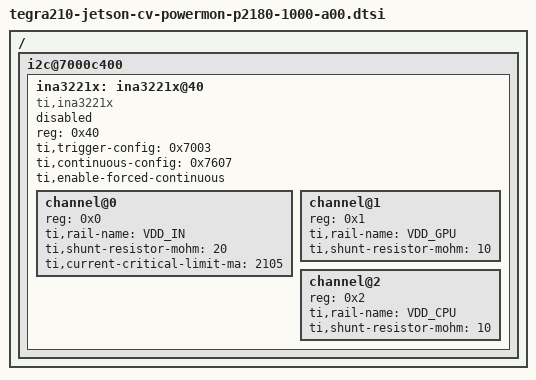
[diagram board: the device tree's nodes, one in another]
/*
 * Copyright (c) 2015, NVIDIA CORPORATION.  All rights reserved.
 *
 * This program is free software; you can redistribute it and/or modify
 * it under the terms of the GNU General Public License as published by
 * the Free Software Foundation; version 2 of the License.
 *
 * This program is distributed in the hope that it will be useful, but WITHOUT
 * ANY WARRANTY; without even the implied warranty of MERCHANTABILITY or
 * FITNESS FOR A PARTICULAR PURPOSE.  See the GNU General Public License for
 * more details.
 *
 */

/ {
	i2c@7000c400 {
		ina3221x: ina3221x@40 {
			compatible = "ti,ina3221x";
			reg = <0x40>;
			ti,trigger-config = <0x7003>;
			ti,continuous-config = <0x7607>;
			ti,enable-forced-continuous;
			#io-channel-cells = <1>;
			#address-cells = <1>;
			#size-cells = <0>;
			status = "disabled";

			channel@0 {
				reg = <0x0>;
				ti,rail-name = "VDD_IN";
				ti,shunt-resistor-mohm = <20>;
				ti,current-critical-limit-ma = <2105>;
			};

			channel@1 {
				reg = <0x1>;
				ti,rail-name = "VDD_GPU";
				ti,shunt-resistor-mohm = <10>;
			};

			channel@2 {
				reg = <0x2>;
				ti,rail-name = "VDD_CPU";
				ti,shunt-resistor-mohm = <10>;
			};
		};
	};
};
